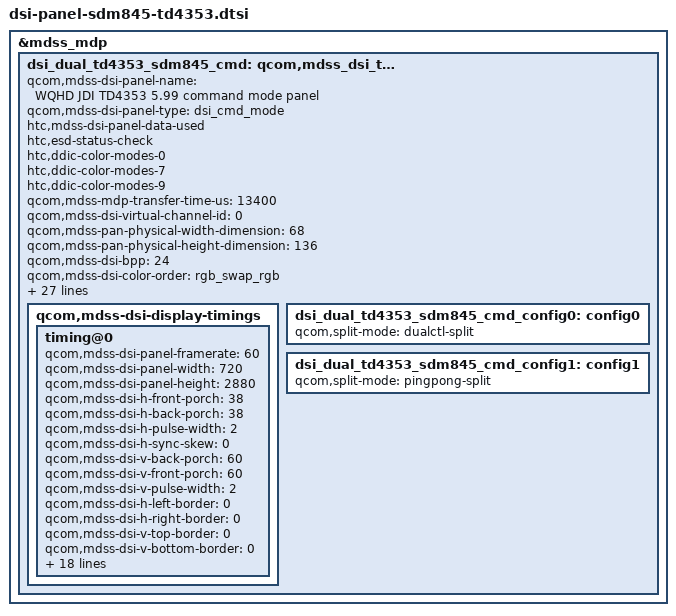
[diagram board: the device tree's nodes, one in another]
/* Copyright (c) 2016-2017, The Linux Foundation. All rights reserved.
 *
 * This program is free software; you can redistribute it and/or modify
 * it under the terms of the GNU General Public License version 2 and
 * only version 2 as published by the Free Software Foundation.
 *
 * This program is distributed in the hope that it will be useful,
 * but WITHOUT ANY WARRANTY; without even the implied warranty of
 * MERCHANTABILITY or FITNESS FOR A PARTICULAR PURPOSE.  See the
 * GNU General Public License for more details.
 */

&mdss_mdp {
	dsi_dual_td4353_sdm845_cmd: qcom,mdss_dsi_td4353_sdm845_wqhd_cmd{
		qcom,mdss-dsi-panel-name =
			"WQHD JDI TD4353 5.99 command mode panel";
		qcom,mdss-dsi-panel-type = "dsi_cmd_mode";
		htc,mdss-dsi-panel-data-used;
		htc,esd-status-check;
		htc,ddic-color-modes-0;
		htc,ddic-color-modes-7;
		htc,ddic-color-modes-9;
		qcom,mdss-mdp-transfer-time-us = <13400>;
		qcom,mdss-dsi-virtual-channel-id = <0>;
		qcom,mdss-pan-physical-width-dimension  = <68>;
		qcom,mdss-pan-physical-height-dimension = <136>;
		qcom,mdss-dsi-bpp = <24>;
		qcom,mdss-dsi-color-order = "rgb_swap_rgb";
		qcom,mdss-dsi-underflow-color = <0xff>;
		qcom,mdss-dsi-border-color = <0>;
		qcom,mdss-dsi-traffic-mode = "non_burst_sync_event";
		qcom,mdss-dsi-bllp-eof-power-mode;
		qcom,mdss-dsi-bllp-power-mode;
		qcom,mdss-dsi-lane-0-state;
		qcom,mdss-dsi-lane-1-state;
		qcom,mdss-dsi-lane-2-state;
		qcom,mdss-dsi-lane-3-state;
		qcom,mdss-dsi-reset-sequence = <0 10>,<1 50>;
		htc,rst-keep-high;
		qcom,mdss-dsi-dma-trigger = "trigger_sw";
		qcom,mdss-dsi-mdp-trigger = "none";
		qcom,mdss-dsi-wr-mem-start = <0x2c>;
		qcom,mdss-dsi-wr-mem-continue = <0x3c>;
		qcom,mdss-dsi-te-dcs-command = <1>;
		qcom,mdss-dsi-panel-status-command = [06 01 00 01 05 00 02 0A 00];
		qcom,mdss-dsi-panel-status-command-state = "dsi_hs_mode";
		qcom,mdss-dsi-lp11-init;
		qcom,mdss-dsi-panel-hdr-enabled;
		qcom,mdss-dsi-panel-hdr-color-primaries = <14500 15500 32000
			17000 15500 30000 8000 3000>;
		qcom,mdss-dsi-panel-peak-brightness = <4200000>;
		qcom,mdss-dsi-panel-blackness-level = <3230>;
		qcom,mdss-dsi-display-timings {
			timing@0 {
				qcom,mdss-dsi-panel-framerate = <60>;
				qcom,mdss-dsi-panel-width = <720>;
				qcom,mdss-dsi-panel-height = <2880>;
				qcom,mdss-dsi-h-front-porch = <38>;
				qcom,mdss-dsi-h-back-porch = <38>;
				qcom,mdss-dsi-h-pulse-width = <2>;
				qcom,mdss-dsi-h-sync-skew = <0>;
				qcom,mdss-dsi-v-back-porch = <60>;
				qcom,mdss-dsi-v-front-porch = <60>;
				qcom,mdss-dsi-v-pulse-width = <2>;
				qcom,mdss-dsi-h-left-border = <0>;
				qcom,mdss-dsi-h-right-border = <0>;
				qcom,mdss-dsi-v-top-border = <0>;
				qcom,mdss-dsi-v-bottom-border = <0>;
				qcom,mdss-dsi-h-sync-pulse = <0>;
				qcom,mdss-dsi-panel-jitter = <0x5 0x1>;
				qcom,mdss-dsi-on-command = [
					39 01 00 00 00 00 05 2A 00 00 05 9F /* soft reset */
					39 01 00 00 00 00 05 2B 00 00 0B 3F /* soft reset */
					39 01 00 00 00 00 03 44 00 00
					15 01 00 00 00 00 02 35 00 			/* TE on */
					15 01 00 00 00 00 02 36 00
					15 01 00 00 00 00 02 3A 77
					39 01 00 00 00 00 05 30 00 00 0B 3F
					23 01 00 00 00 00 02 B0 00 			/*root open*/
					23 01 00 00 00 00 02 D6 40 			/*gamma*/
					23 01 00 00 00 00 02 B0 03 			/*root close*/
					05 01 00 00 46 00 02 11 00 			/* sleep out */
					05 01 00 00 28 00 02 29 00 			/* display on */
					39 01 00 00 00 00 03 51 FF F0
					15 01 00 00 00 00 02 53 24			/* dimming disable */
					23 01 00 00 00 00 02 B0 00 						/*root open*/
					15 01 00 00 00 00 02 55 82						/* CABC still mode*/
					39 01 00 00 00 00 08 B8 57 3D 19 BE 1E 0A 0A	/* C1 */
					39 01 00 00 00 00 08 B9 89 59 04 BC 28 00 06	/* C2 */
					39 01 00 00 00 00 08 BA CD 33 27 BE 64 00 00	/* C3 */
					39 01 00 00 00 00 15 CE BB 40 49 53 59 5E 63 68 6E 74 7E 8A 98 A8 BB D0 E7 FF 04 28 /* PWM setting */
					23 01 00 00 00 00 02 B0 04
					39 01 00 00 00 00 02 F9 46
					23 01 00 00 00 00 02 B0 03 						/*root close*/
				];
				qcom,mdss-dsi-off-command = [
					05 01 00 00 14 00 02 28 00
					05 01 00 00 00 00 02 34 00
					05 01 00 00 50 00 02 10 00
				];
				htc,dimming-on-cmds = [39 01 00 00 00 00 02 53 2C];
				htc,mdss-dsi-ddic-color-native = [
					39 01 00 00 00 00 02 B0 00
					39 01 00 00 00 00 42 CA 1D FC FC FC 00 00 00 00 00 00 00 00 00 00 00 00 00 00 00 00 00 00 00 00 00 00 00 00 00 00 00 00 00 00 00 00 00 00 00 00 00 00 00 00 00 00 00 00 00 00 00 00 00 00 00 00 00 00 00 00 00 00 00 00 00
					39 01 00 00 00 00 02 B0 04
					];
				htc,mdss-dsi-ddic-color-srgb = [
					39 01 00 00 00 00 02 B0 00
					39 01 00 00 00 00 42 CA 1D FC 9C 6C F8 DF ED CD E5 D1 D7 F7 CC C3 EF E6 D1 D5 CD D5 D3 D8 FF 00 00 EE 36 19 FF 00 FF 00 70 E4 3F FF 00 00 FF 22 00 D6 FF 00 FF FF 74 E4 DC FF FF 00 FF EC 32 D5 FF FF FF 00 FF E9 41 FF 00
					39 01 00 00 00 00 02 B0 04
					];
				htc,mdss-dsi-ddic-color-dci-p3 = [
					39 01 00 00 00 00 02 B0 00
					39 01 00 00 00 00 42 CA 1D FC C8 C4 F1 E3 E9 E8 00 F4 E2 ED CD EF ED EF FA EC E1 EE E4 EF FF 00 00 FF 1B 00 FF 00 FF 00 00 F3 00 FF 00 00 FF 27 00 F5 FF 00 FF FF 00 F2 F4 FF FF 00 FF FD 0A EE FF FF FF 00 FD F3 00 FF 00
					39 01 00 00 00 00 02 B0 04
					];
				qcom,mdss-dsi-on-command-state = "dsi_lp_mode";
				qcom,mdss-dsi-off-command-state = "dsi_hs_mode";
				qcom,mdss-dsi-default-command-state = "dsi_hs_mode";
			};
		};
		dsi_dual_td4353_sdm845_cmd_config0: config0 {
			qcom,split-mode = "dualctl-split";
		};

		dsi_dual_td4353_sdm845_cmd_config1: config1 {
			qcom,split-mode = "pingpong-split";
		};
	};
};
